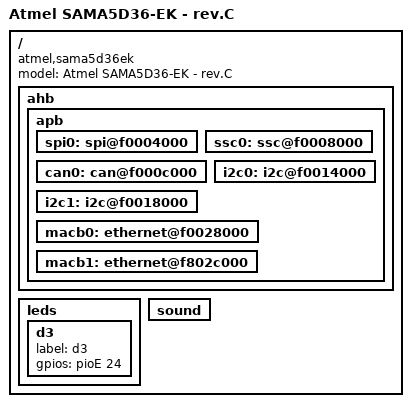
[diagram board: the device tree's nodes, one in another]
/*
 * sama5d36ek_revc.dts - Device Tree file for SAMA5D36-EK up to rev.C MB
 *
 *  Copyright (C) 2013 Atmel,
 *                2013 Josh Wu <josh.wu@atmel.com>
 *
 * Licensed under GPLv2 or later.
 */
/dts-v1/;
#include "sama5d36.dtsi"
#include "sama5d3xmb.dtsi"
#include "sama5d3xmb_revc_audio.dtsi"		/* require i2c0 */
#include "sama5d3xmb_revc_hdmi.dtsi"		/* require i2c0 */
/* #include "sama5d3xmb_isi_sensors.dtsi"*/	/* Conflict with i2c0 & led d3 */
#include "sama5d3xdm.dtsi"

/ {
	model = "Atmel SAMA5D36-EK - rev.C";
	compatible = "atmel,sama5d36ek", "atmel,sama5d3xmb", "atmel,sama5d3xcm", "atmel,sama5d36", "atmel,sama5d3", "atmel,sama5";

	ahb {
		apb {
			spi0: spi@f0004000 {
				status = "okay";
			};

			ssc0: ssc@f0008000 {
				status = "okay";
			};

			can0: can@f000c000 {
				status = "okay";
			};

			i2c0: i2c@f0014000 {
				status = "okay";
			};

			i2c1: i2c@f0018000 {
				status = "okay";
			};

			macb0: ethernet@f0028000 {
				status = "okay";
			};

			macb1: ethernet@f802c000 {
				status = "okay";
			};
		};
	};

	leds {
		d3 {
			label = "d3";
			gpios = <&pioE 24 GPIO_ACTIVE_HIGH>;
		};
	};

	sound {
		status = "okay";
	};
};
